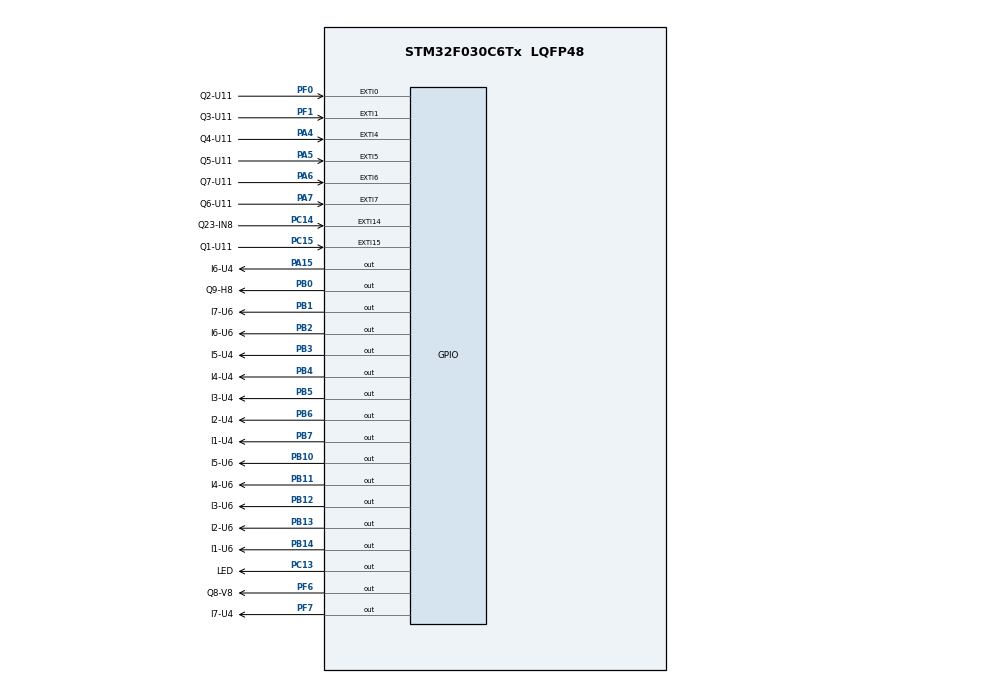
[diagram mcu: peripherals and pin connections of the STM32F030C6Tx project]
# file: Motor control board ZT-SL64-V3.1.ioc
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Mcu.Family=STM32F0
Mcu.Name=STM32F030C6Tx
Mcu.Package=LQFP48
NVIC.EXTI0_1_IRQn=true\:0\:0\:false\:false\:true\:true\:true\:true
NVIC.EXTI4_15_IRQn=true\:0\:0\:false\:false\:true\:true\:true\:true
PA13.Mode=Serial_Wire
PA13.Signal=SYS_SWDIO
PA14.Mode=Serial_Wire
PA14.Signal=SYS_SWCLK
PA15.GPIO_Label=I6-U4
PA15.Signal=GPIO_Output
PA4.GPIO_Label=Q4-U11
PA4.GPIO_ModeDefaultEXTI=GPIO_MODE_IT_FALLING
PA4.GPIO_PuPd=GPIO_NOPULL
PA4.Signal=GPXTI4
PA5.GPIO_Label=Q5-U11
PA5.GPIO_ModeDefaultEXTI=GPIO_MODE_IT_FALLING
PA5.GPIO_PuPd=GPIO_NOPULL
PA5.Signal=GPXTI5
PA6.GPIO_Label=Q7-U11
PA6.GPIO_ModeDefaultEXTI=GPIO_MODE_IT_FALLING
PA6.GPIO_PuPd=GPIO_NOPULL
PA6.Signal=GPXTI6
PA7.GPIO_Label=Q6-U11
PA7.GPIO_ModeDefaultEXTI=GPIO_MODE_IT_FALLING
PA7.GPIO_PuPd=GPIO_PULLUP
PA7.Signal=GPXTI7
PB0.GPIO_Label=Q9-H8
PB0.PinState=GPIO_PIN_SET
PB0.Signal=GPIO_Output
PB1.GPIO_Label=I7-U6
PB1.PinState=GPIO_PIN_SET
PB1.Signal=GPIO_Output
PB10.GPIO_Label=I5-U6
PB10.PinState=GPIO_PIN_SET
PB10.Signal=GPIO_Output
PB11.GPIO_Label=I4-U6
PB11.PinState=GPIO_PIN_SET
PB11.Signal=GPIO_Output
PB12.GPIO_Label=I3-U6
PB12.PinState=GPIO_PIN_SET
PB12.Signal=GPIO_Output
PB13.GPIO_Label=I2-U6
PB13.PinState=GPIO_PIN_SET
PB13.Signal=GPIO_Output
PB14.GPIO_Label=I1-U6
PB14.PinState=GPIO_PIN_SET
PB14.Signal=GPIO_Output
PB2.GPIO_Label=I6-U6
PB2.PinState=GPIO_PIN_SET
PB2.Signal=GPIO_Output
PB3.GPIO_Label=I5-U4
PB3.Signal=GPIO_Output
PB4.GPIO_Label=I4-U4
PB4.Signal=GPIO_Output
PB5.GPIO_Label=I3-U4
PB5.Signal=GPIO_Output
PB6.GPIO_Label=I2-U4
PB6.Signal=GPIO_Output
PB7.GPIO_Label=I1-U4
PB7.GPIO_PuPd=GPIO_NOPULL
PB7.Signal=GPIO_Output
PC13.GPIO_Label=LED
PC13.PinState=GPIO_PIN_SET
PC13.Signal=GPIO_Output
PC14-OSC32_IN.GPIO_Label=Q23-IN8
PC14-OSC32_IN.GPIO_ModeDefaultEXTI=GPIO_MODE_IT_FALLING
PC14-OSC32_IN.GPIO_PuPd=GPIO_NOPULL
PC14-OSC32_IN.Signal=GPXTI14
PC15-OSC32_OUT.GPIO_Label=Q1-U11
PC15-OSC32_OUT.GPIO_ModeDefaultEXTI=GPIO_MODE_IT_FALLING
PC15-OSC32_OUT.GPIO_PuPd=GPIO_NOPULL
PC15-OSC32_OUT.Signal=GPXTI15
PF0-OSC_IN.GPIO_Label=Q2-U11
PF0-OSC_IN.GPIO_ModeDefaultEXTI=GPIO_MODE_IT_FALLING
PF0-OSC_IN.GPIO_PuPd=GPIO_NOPULL
PF0-OSC_IN.Signal=GPXTI0
PF1-OSC_OUT.GPIO_Label=Q3-U11
PF1-OSC_OUT.GPIO_ModeDefaultEXTI=GPIO_MODE_IT_FALLING
PF1-OSC_OUT.GPIO_PuPd=GPIO_NOPULL
PF1-OSC_OUT.Signal=GPXTI1
PF6.GPIO_Label=Q8-V8
PF6.Signal=GPIO_Output
PF7.GPIO_Label=I7-U4
PF7.Signal=GPIO_Output
ProjectManager.HeapSize=0x200
ProjectManager.StackSize=0x400
ProjectManager.TargetToolchain=STM32CubeIDE
board=custom

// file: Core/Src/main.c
/* USER CODE BEGIN Header */
/**
  ******************************************************************************
  * @file           : main.c
  * @brief          : Main program body
  ******************************************************************************
  * @attention
  *
  * Copyright (c) 2023 STMicroelectronics.
  * All rights reserved.
  *
  * This software is licensed under terms that can be found in the LICENSE file
  * in the root directory of this software component.
  * If no LICENSE file comes with this software, it is provided AS-IS.
  *
  ******************************************************************************
  */
/* USER CODE END Header */
#include "main.h"

/* USER CODE BEGIN Includes */
#include "rotate_motor.h"
/* USER CODE END Includes */

/* USER CODE BEGIN PD */
uint16_t counter = 0;
/* USER CODE END PD */

void SystemClock_Config(void);
static void MX_GPIO_Init(void);

int main(void)
{

  /* MCU Configuration--------------------------------------------------------*/

  /* Reset of all peripherals, Initializes the Flash interface and the Systick. */
  HAL_Init();

  /* Configure the system clock */
  SystemClock_Config();

  /* Initialize all configured peripherals */
  MX_GPIO_Init();
  /* USER CODE BEGIN 2 */

  HAL_GPIO_WritePin(LED_GPIO_Port, LED_Pin, GPIO_PIN_RESET);
  rotate_motor(1);
  /* USER CODE END 2 */

  /* Infinite loop */
  while (1){

  }
}

void SystemClock_Config(void)
{
  RCC_OscInitTypeDef RCC_OscInitStruct = {0};
  RCC_ClkInitTypeDef RCC_ClkInitStruct = {0};

  /** Initializes the RCC Oscillators according to the specified parameters
  * in the RCC_OscInitTypeDef structure.
  */
  RCC_OscInitStruct.OscillatorType = RCC_OSCILLATORTYPE_HSI;
  RCC_OscInitStruct.HSIState = RCC_HSI_ON;
  RCC_OscInitStruct.HSICalibrationValue = RCC_HSICALIBRATION_DEFAULT;
  RCC_OscInitStruct.PLL.PLLState = RCC_PLL_NONE;
  if (HAL_RCC_OscConfig(&RCC_OscInitStruct) != HAL_OK)
  {
    Error_Handler();
  }

  /** Initializes the CPU, AHB and APB buses clocks
  */
  RCC_ClkInitStruct.ClockType = RCC_CLOCKTYPE_HCLK|RCC_CLOCKTYPE_SYSCLK
                              |RCC_CLOCKTYPE_PCLK1;
  RCC_ClkInitStruct.SYSCLKSource = RCC_SYSCLKSOURCE_HSI;
  RCC_ClkInitStruct.AHBCLKDivider = RCC_SYSCLK_DIV1;
  RCC_ClkInitStruct.APB1CLKDivider = RCC_HCLK_DIV1;

  if (HAL_RCC_ClockConfig(&RCC_ClkInitStruct, FLASH_LATENCY_0) != HAL_OK)
  {
    Error_Handler();
  }
}

static void MX_GPIO_Init(void)
{
  GPIO_InitTypeDef GPIO_InitStruct = {0};

  /* GPIO Ports Clock Enable */
  __HAL_RCC_GPIOC_CLK_ENABLE();
  __HAL_RCC_GPIOF_CLK_ENABLE();
  __HAL_RCC_GPIOA_CLK_ENABLE();
  __HAL_RCC_GPIOB_CLK_ENABLE();

  /*Configure GPIO pin Output Level */
  HAL_GPIO_WritePin(LED_GPIO_Port, LED_Pin, GPIO_PIN_SET);

  /*Configure GPIO pin Output Level */
  HAL_GPIO_WritePin(GPIOB, Q9_H8_Pin|I7_U6_Pin|I6_U6_Pin|I5_U6_Pin
                          |I4_U6_Pin|I3_U6_Pin|I2_U6_Pin|I1_U6_Pin, GPIO_PIN_SET);

  /*Configure GPIO pin Output Level */
  HAL_GPIO_WritePin(GPIOF, Q8_V8_Pin|I7_U4_Pin, GPIO_PIN_RESET);

  /*Configure GPIO pin Output Level */
  HAL_GPIO_WritePin(I6_U4_GPIO_Port, I6_U4_Pin, GPIO_PIN_RESET);

  /*Configure GPIO pin Output Level */
  HAL_GPIO_WritePin(GPIOB, I5_U4_Pin|I4_U4_Pin|I3_U4_Pin|I2_U4_Pin
                          |I1_U4_Pin, GPIO_PIN_RESET);

  /*Configure GPIO pin : LED_Pin */
  GPIO_InitStruct.Pin = LED_Pin;
  GPIO_InitStruct.Mode = GPIO_MODE_OUTPUT_PP;
  GPIO_InitStruct.Pull = GPIO_NOPULL;
  GPIO_InitStruct.Speed = GPIO_SPEED_FREQ_LOW;
  HAL_GPIO_Init(LED_GPIO_Port, &GPIO_InitStruct);

  /*Configure GPIO pins : Q23_IN8_Pin Q1_U11_Pin */
  GPIO_InitStruct.Pin = Q23_IN8_Pin|Q1_U11_Pin;
  GPIO_InitStruct.Mode = GPIO_MODE_IT_FALLING;
  GPIO_InitStruct.Pull = GPIO_NOPULL;
  HAL_GPIO_Init(GPIOC, &GPIO_InitStruct);

  /*Configure GPIO pins : Q2_U11_Pin Q3_U11_Pin */
  GPIO_InitStruct.Pin = Q2_U11_Pin|Q3_U11_Pin;
  GPIO_InitStruct.Mode = GPIO_MODE_IT_FALLING;
  GPIO_InitStruct.Pull = GPIO_NOPULL;
  HAL_GPIO_Init(GPIOF, &GPIO_InitStruct);

  /*Configure GPIO pins : Q4_U11_Pin Q5_U11_Pin Q7_U11_Pin */
  GPIO_InitStruct.Pin = Q4_U11_Pin|Q5_U11_Pin|Q7_U11_Pin;
  GPIO_InitStruct.Mode = GPIO_MODE_IT_FALLING;
  GPIO_InitStruct.Pull = GPIO_NOPULL;
  HAL_GPIO_Init(GPIOA, &GPIO_InitStruct);

  /*Configure GPIO pin : Q6_U11_Pin */
  GPIO_InitStruct.Pin = Q6_U11_Pin;
  GPIO_InitStruct.Mode = GPIO_MODE_IT_FALLING;
  GPIO_InitStruct.Pull = GPIO_PULLUP;
  HAL_GPIO_Init(Q6_U11_GPIO_Port, &GPIO_InitStruct);

  /*Configure GPIO pins : Q9_H8_Pin I7_U6_Pin I6_U6_Pin I5_U6_Pin
                           I4_U6_Pin I3_U6_Pin I2_U6_Pin I1_U6_Pin
                           I5_U4_Pin I4_U4_Pin I3_U4_Pin I2_U4_Pin
                           I1_U4_Pin */
  GPIO_InitStruct.Pin = Q9_H8_Pin|I7_U6_Pin|I6_U6_Pin|I5_U6_Pin
                          |I4_U6_Pin|I3_U6_Pin|I2_U6_Pin|I1_U6_Pin
                          |I5_U4_Pin|I4_U4_Pin|I3_U4_Pin|I2_U4_Pin
                          |I1_U4_Pin;
  GPIO_InitStruct.Mode = GPIO_MODE_OUTPUT_PP;
  GPIO_InitStruct.Pull = GPIO_NOPULL;
  GPIO_InitStruct.Speed = GPIO_SPEED_FREQ_LOW;
  HAL_GPIO_Init(GPIOB, &GPIO_InitStruct);

  /*Configure GPIO pins : Q8_V8_Pin I7_U4_Pin */
  GPIO_InitStruct.Pin = Q8_V8_Pin|I7_U4_Pin;
  GPIO_InitStruct.Mode = GPIO_MODE_OUTPUT_PP;
  GPIO_InitStruct.Pull = GPIO_NOPULL;
  GPIO_InitStruct.Speed = GPIO_SPEED_FREQ_LOW;
  HAL_GPIO_Init(GPIOF, &GPIO_InitStruct);

  /*Configure GPIO pin : I6_U4_Pin */
  GPIO_InitStruct.Pin = I6_U4_Pin;
  GPIO_InitStruct.Mode = GPIO_MODE_OUTPUT_PP;
  GPIO_InitStruct.Pull = GPIO_NOPULL;
  GPIO_InitStruct.Speed = GPIO_SPEED_FREQ_LOW;
  HAL_GPIO_Init(I6_U4_GPIO_Port, &GPIO_InitStruct);

  /* EXTI interrupt init*/
  HAL_NVIC_SetPriority(EXTI0_1_IRQn, 0, 0);
  HAL_NVIC_EnableIRQ(EXTI0_1_IRQn);

  HAL_NVIC_SetPriority(EXTI4_15_IRQn, 0, 0);
  HAL_NVIC_EnableIRQ(EXTI4_15_IRQn);

}

/* USER CODE BEGIN 4 */
void HAL_GPIO_EXTI_Callback(uint16_t GPIO_Pin)

{
	counter++;
	if ((GPIO_Pin == Q6_U11_Pin) && counter >= 6){
		counter = 0;
	set_start_position();
	HAL_GPIO_WritePin(LED_GPIO_Port, LED_Pin, GPIO_PIN_SET);
	}
}
/* USER CODE END 4 */

void Error_Handler(void)
{
  __disable_irq();
  while (1)
  {
  }
}
